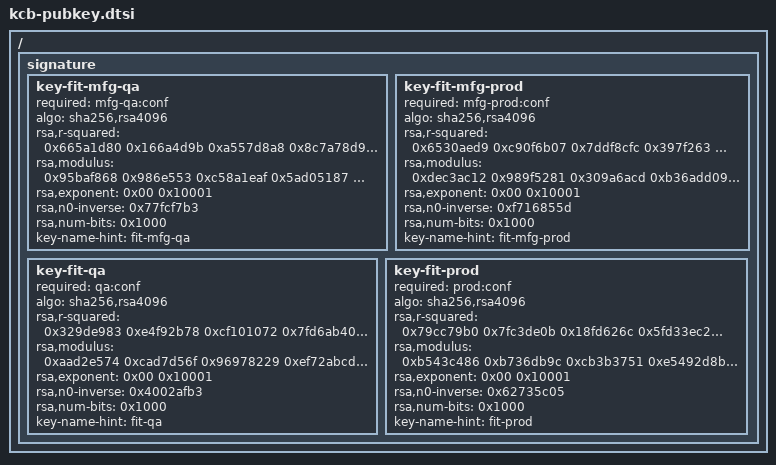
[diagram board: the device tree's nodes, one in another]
/*
 * This is a Device Tree representation of the public keys that will
 * be used for FIT image verification.
 *
 * The procedure to generate this file from production keys in AWS CloudHSM is
 * avaliable here:
 * https://github.com/ChargePoint/emb-platform/blob/master/os/buildroot/package/emb-sbsigner/README.md
 */

/ {
	signature {

		key-fit-mfg-qa {
			required = "mfg-qa:conf";
			algo = "sha256,rsa4096";
			rsa,r-squared = < 0x665a1d80 0x166a4d9b 0xa557d8a8 0x8c7a78d9 0xf4e15c7b 0x11d93e83 0x64c54e9 0x7944ce6d 0x9000c1e 0x2295f4a 0xd1a5fc97 0x77da3ca4 0x1b8357ea 0x234455da 0x6d49fc74 0xb5c791c3 0x6a1985e 0xd7bc98fe 0x99637999 0x23d22882 0xdf1b20ab 0xff6c3c1a 0x8fd6c9c0 0x9d0add75 0xc0ef7f4 0x50fc9978 0xc47e80b2 0x6f125df8 0xec1073dc 0x2f2a7b23 0xad07317b 0x1400cfc0 0x6a585a28 0x58035780 0xa6b94682 0x820d5604 0xa53b9264 0xca8510c2 0xe2faae05 0xe184be7d 0xabcadbfc 0x46a3d077 0x3e004b39 0x4a07fcae 0x2660e2df 0x7a564f5b 0xd662b66 0x24f41f32 0xe8a6f6ba 0xe0b936cc 0x3c117b2e 0x5bb8b08b 0xbe9539f 0xf0b96eed 0x78cf169c 0x366a11bb 0x7a88ccee 0xa0d228f0 0xa6286849 0xae9a5153 0xed4c8f47 0x65d77a7d 0xf5faf94f 0x6355354f 0xbc6f77ae 0x71292cf 0xeada07a4 0x3f66607f 0xf7903a5e 0xdbd3837d 0x27178acb 0xa314230c 0x648adc27 0x171ced02 0xe3ffe486 0x7680e5fa 0x5f1511e7 0xc39d7470 0x4a8c0c61 0x90b3ad1f 0x6a96369b 0xf6d0c01a 0x34ad94e5 0x8c3051bd 0xc1ac5da6 0x318d077a 0x41f7cdbb 0x6f7f253d 0x4dad6e19 0x1519bc15 0xc6d3a77f 0x11921fbf 0x3f651807 0xe66b9d78 0xec6acb9c 0xcce77610 0xc942a9e7 0xfe8b93c2 0x5f5dee2c 0x10aaddc8 0xbf092e31 0x4ace182f 0x5bd5b84 0x7e3dd261 0x1323e825 0x6c4ae565 0x42d04632 0x787533b 0xde8bde8d 0xbb8170a1 0x7d350d0b 0x1bdedb5c 0xa7bf46c4 0x362c3ac1 0x4815d47f 0x5c8d2e98 0xe0408e65 0x32ad9b76 0x66ce398e 0xffe2d7ac 0xa14f52d0 0xb356d627 0x363041f8 0xa34d1052 0x7e8841ad 0x3e4e854e 0xde868242 0x19837be6 >;
			rsa,modulus = < 0x95baf868 0x986e553 0xc58a1eaf 0x5ad05187 0x7ce40511 0x86014554 0xb3c815d9 0x901bd41e 0x43239485 0x18defb91 0xd405c901 0x937d3d73 0x4b5d996e 0x49013fc8 0x520905b 0x4907d265 0x74e9965e 0xa2f64a33 0x5e23236e 0xa621313d 0x32318fe1 0x2b8642b 0xec9756b7 0x1768c628 0xcb2e6487 0xb4c4f324 0x4c3b3e87 0x6fc41ca8 0x5b96bf1d 0x52787842 0xb1a60463 0x57fab426 0x548b10df 0x708c9e34 0x7a86e6eb 0x8346990d 0x5a221779 0x8c36c9b5 0xd485b546 0xcbac1bd4 0x68e064c1 0xf93f17cf 0xeb964a31 0x2fa5f456 0x497ccddc 0x99c38950 0xb209ac0e 0xd881d00b 0xfd7b074f 0x40500044 0x25fb6454 0xdef0664e 0x6004b7c6 0xfe23c787 0x6018945e 0x42ca113f 0x1d92036c 0xa0869953 0x6ed8e283 0xd9fe6b4a 0x9474b3fb 0xa3487675 0xee8cbb9f 0x77d65730 0x31c7ab0b 0x9c8635bb 0x1c6a4768 0x533cf705 0xd94d1691 0x18b6ac7e 0xbe3ce926 0x38fb4fa5 0x5a768315 0x118627ba 0x398c150a 0x1f08e67f 0x12fe838b 0xe1f0319f 0xf67ca964 0x1da8f6e5 0x4af92c55 0x8b1b479 0x5b8c942f 0xb7ee292 0x5781db32 0xa836320a 0xfd6374ad 0x2d4cb2d7 0xaafaf79a 0x5994ed63 0xdec3a71e 0x733b630c 0xf2f8826c 0x6cab20a1 0x9b09b897 0xc0703c9e 0x510bbe87 0xc1a5be9e 0x3fe6b7a 0x26d2068e 0x3fa08838 0xfa927363 0x5ee35f18 0x1c86c851 0x8976d97a 0xef71def4 0xa5d2d66b 0xb6a63d0c 0xb632811a 0xe6fc1176 0xf1a12d01 0xc3577fb 0x100e6c3e 0x734535a0 0x4e883689 0xc6362ad0 0x72e5fb9b 0x15941d88 0x49cf0a0d 0xc1c5c987 0x600df83 0x827905ba 0xdf28dab4 0x4576ffd3 0x12212c14 0xb9d31561 0x9654d0fe 0x43777085 >;
			rsa,exponent = < 0x00 0x10001 >;
			rsa,n0-inverse = < 0x77fcf7b3 >;
			rsa,num-bits = < 0x1000 >;
			key-name-hint = "fit-mfg-qa";
		};

		key-fit-mfg-prod {
			required = "mfg-prod:conf";
			algo = "sha256,rsa4096";
			rsa,r-squared = < 0x6530aed9 0xc90f6b07 0x7ddf8cfc 0x397f263 0x447e964f 0x468cea87 0x38af5adc 0xf4a42d1f 0x59ecaecf 0xd216f09 0x818d93e 0xb25de89 0xe0ef48ce 0xe1ab2158 0xbd1cae78 0xec078ef8 0x1c44b711 0xa61aae4a 0x18458872 0x879389bb 0xa29663d0 0x58661d9c 0x401fbf5e 0xe2b112a8 0xf26953e7 0xf081550d 0xf03f828e 0x460cc5b2 0xe991d252 0x4e60ca01 0xe0c2f80d 0x8c521f46 0x44655ccb 0xb51f60ec 0x62750c93 0xfb07dd4a 0x817e97f6 0xd6853c02 0xb2169907 0x354f9 0xbc2ba728 0x6983cbfe 0xb3e90779 0x8d121e9c 0xe84bb6f9 0x77c1e260 0x3d374193 0x41948878 0xb6da228b 0x94dc9473 0x10d7fba0 0xe90d214a 0x241862d1 0x1b3dd3ff 0xb026b871 0xfa5a4d23 0x879b2a11 0xa967ca89 0x690c68dc 0x1d0b27d9 0x7dd14669 0x4f2be452 0x42a78469 0x396b3dd1 0x7bea96 0x72c8e6b7 0x7f81c043 0x81c20251 0xfbf4cb2b 0x598a22c4 0x69aa6c32 0x44903b07 0xf2fc2b65 0x1e8d30b1 0x7530cad8 0x3791fc53 0x519f8f4c 0x5e668b56 0xc84a138d 0x5282b97a 0x3786e085 0xab014f5e 0xd55dce3c 0x643e7777 0x874a6dfb 0x6da806af 0xbc05f913 0xc4142be4 0x6fb4231d 0x65bf036b 0x38d49fd3 0xf378d8c7 0xcf81e3b4 0xc1abf106 0x962822e0 0x8b5ad19c 0x7d976a11 0x26e16da9 0x23d531d6 0x6ba3a07d 0x862ee83d 0x18bfc294 0x808aebb3 0x74c178b4 0x4e9124bb 0x7c2f21cc 0x9c39c1c7 0x14470bd 0x6fe64f00 0x85ee086d 0x4de95dcf 0x463e4eaf 0x7bc21b88 0xb0e12312 0x6a773f45 0xe6dc068b 0xb0b8cbf 0xce642af2 0x71a737d3 0x2826e57d 0xd6bd9c94 0x96aa1787 0x4432ba50 0x200ac7d3 0x2898c832 0x77e04d9d 0x31f80a71 0x26aa3f49 >;
			rsa,modulus = < 0xdec3ac12 0x989f5281 0x309a6acd 0xb36add09 0x82cf2881 0x7c807d85 0xf091a9b0 0xb5b464d 0x5328e494 0x284b67d0 0x1a620d34 0xfd6c278 0xc7bcbb0a 0xc157f7dc 0xfd741521 0x906061b0 0xb62c43d7 0x4d7fdcc 0x98acd57c 0xca05f664 0xd330aca4 0xe32b3161 0xc75e039c 0xb574df5f 0xb506eaf2 0xc721edb0 0x92276684 0xcfa73716 0xb9e73f17 0xbef008f 0xc5e1f72b 0x78623de7 0xac80d3ff 0xddf2c332 0x8ec6971 0x3bc2313 0x9d644dfe 0x8d930a0 0xbaa87cd5 0xc0d80ad9 0xf63e9ede 0xf08ca23b 0x1adac644 0x1257d918 0xfe82133 0xc3148cc2 0xa9c69531 0x2ee84904 0xa6bd2870 0x6a7bf93c 0x960dbe7c 0x56d799e6 0x1919631a 0x17b26518 0x7e568e37 0xb0ca2e9d 0x48f45a2e 0x6b22057a 0x96acf7f8 0xc2cc811b 0xcdaa0110 0x8cc8c082 0xb35696fa 0xb742a3db 0xd503ec37 0xa392e2be 0xb779d8f 0xe90ebd9d 0x324243c2 0xd63182fb 0x67dc3eb8 0xf3f083c5 0xc6dfc5fc 0x1fd3608a 0xdccab82a 0xbb3e17a 0x5b58df2e 0xa35ae29b 0x2e72caec 0xb38f5392 0x70bb59d6 0x37cea7f4 0xa37ad698 0x1154cf58 0x6ac947c4 0x888e0cf1 0x69c9456c 0xb56e39b7 0x59c927b1 0xa4b3f5e1 0x9da87d07 0x7fac7d3a 0x43b19eef 0xc3966f49 0xc85b6d24 0xe1174524 0x8db07179 0x703df686 0xa6416bd5 0x3fc1938e 0xc998168a 0x53a7704 0x687dbb13 0x48bc8a0 0x2cb4d29e 0x34cb759c 0x821a7f8 0xc2c2f87c 0xadd55119 0x9f657819 0x6e5d6c37 0x560320bf 0x82ff0b8c 0x36602ce3 0x38c8b45f 0x5bf899c0 0xa1f9e46a 0xdee7e23d 0xc5020370 0xf62644df 0xb442a8fc 0xa10d081b 0x9ab9a7b 0xe4c90dae 0x5c3aad30 0xfcce34ac 0xe41163bc 0x6738090b >;
			rsa,exponent = < 0x00 0x10001 >;
			rsa,n0-inverse = < 0xf716855d >;
			rsa,num-bits = < 0x1000 >;
			key-name-hint = "fit-mfg-prod";
		};

		key-fit-qa {
			required = "qa:conf";
			algo = "sha256,rsa4096";
			rsa,r-squared = < 0x329de983 0xe4f92b78 0xcf101072 0x7fd6ab40 0x157e59af 0xc1a78b92 0xb94cb04b 0xb9ba3528 0x357234b 0x1a10217c 0x36ac84f0 0x33a30730 0xe63306aa 0xd62369af 0x1bf3cab3 0xffbb5551 0xbd310632 0x416a2137 0x4bf5ac3b 0x6db17e21 0xd2dd36f6 0x32a1ab4e 0x418d6247 0x1dc7d282 0xcebbe3e0 0xe72be447 0xd7e26d2f 0x7ad54a8e 0x42e74184 0x87418b4a 0x46265ee 0x84c6775d 0x13caa243 0xdbc81fa7 0x96341fcb 0xcda23404 0xbea4a853 0x69e87aae 0x960ad7ba 0x8b5f5627 0xfa9a8291 0xcbd63883 0x20008885 0xa97818a3 0xf0902ed6 0xefbd7ae5 0x219efdec 0xae0bd7c0 0xded898a 0x47d266f8 0x54f19218 0xdf7283b8 0x788c3692 0x5072eaf5 0x5f206e15 0xda86467b 0xb677a840 0x8405c0db 0x2cc1eb13 0x1ee4f492 0x2ecbb70b 0x16507d4 0xea24827e 0x46a433f1 0xc7e0ab9a 0xc77e7f76 0x8e51d831 0xd071cc06 0x9afabccf 0x277ea53 0xb0a82ed 0x7fa851fc 0xdea9f0ef 0x99e13e74 0x5f2af4fe 0xd4b37208 0x9f232e6e 0x3658370d 0x6e471d1e 0x7f7597f7 0x128624bc 0xe9e24a0 0x3fa78144 0x4e391483 0x613c97b7 0x302523ec 0xa84cb413 0x60541ee0 0x653c937a 0x5f42b56b 0xcda3b31c 0x3b664ea1 0x1f6715b4 0xd822e001 0x35667953 0x657e9346 0x89579dcd 0xca58f713 0xe0bb181a 0xbd8353f4 0xd56d8419 0xb9569bbd 0x79d91125 0xec9d81a8 0x3d999139 0x49c36d76 0x449b6901 0xafbd6a90 0x1c5d1cac 0x1dcab87a 0xa9cb0f04 0xdfa6f075 0xeca4ee87 0x1ae9ae8b 0x280c5a2b 0xe7145fe 0xe0e1d51e 0x8f7170e7 0x9d67fca5 0xe70baf7f 0xaf4a491b 0x77a4985a 0xcc9bcb3f 0xb0257f57 0x72cc2ce1 0x9db4305c 0x64f375d9 0x4584b73a >;
			rsa,modulus = < 0xaad2e574 0xcad7d56f 0x96978229 0xef72abcd 0xec887fc 0xfa1c0d69 0xe77a4f31 0x7840817e 0x8cf95110 0x69515371 0x9f5a248 0x7c4c73fb 0x5126237e 0xdafc2094 0x7dc2b48f 0x52e23243 0x25b6e881 0xf90d407c 0x22527ea0 0xfa2e29d3 0x13c30f92 0xcbdaad06 0x2bba503d 0x722fc753 0xc19d4861 0x51d70d31 0xf9b84846 0x64a95380 0xe47182c3 0x9139b1c4 0xb122034c 0xff845e8b 0x3331505d 0x52920aa5 0x96027934 0x824e6e83 0x24acb1a9 0x30a4f949 0x45d7e6f3 0xdf6c9cfc 0x1e887ab0 0x94551c13 0x746a9b7f 0xd3d09152 0x4b541e2a 0x52fc49b1 0xd62f5e24 0x78d43a43 0x680c2cce 0x479cae87 0xc4b1076c 0xbbe819e7 0x45a22818 0x7b0e66d5 0x6de8bc13 0x37913057 0x1a74edd3 0x19902352 0x9248fa8a 0x54fd79ee 0xacb39222 0x4c01cedb 0xd431876c 0xb65fb864 0xedfabe45 0xb45dec1e 0xd7701daf 0xd4323b50 0xe356de58 0x2bfdc9ff 0xa0a7a334 0xa04a749 0xb56c9aac 0xdd51a20d 0x3707e33e 0xa8ca9496 0x5f501a82 0x41be062c 0x22927118 0x876d8535 0xebc136dd 0x2f90d391 0xd6b96115 0x5bc8b9ed 0x10ac0cea 0xbcbe887b 0xb0be8be6 0x316f73 0xa7f5ecc9 0x16b3b1b 0xaeba1a31 0x2f528447 0x3b80b861 0x5ae94928 0xf08cd702 0x3a7ceafa 0x34513416 0x20905701 0xd8cb03d1 0xe8c8e3b 0x71162ee2 0x7defdbaa 0x751f262 0xc21a5c82 0x71322eb7 0xf906a3bc 0xb8424bf2 0x620b84dd 0x61a77a34 0xf566795c 0x4ff1210a 0x20d5d873 0xcbdd1712 0x5d0e7965 0xe3ba0f42 0xde989b9b 0x8b9aa9d2 0xb1b3ee17 0x8139d1d 0x1edce668 0xcc68412d 0xbe5811e0 0xa0042db2 0xd796e7e8 0x744c086f 0xe994e600 0xccd5ee93 0x8ede6885 >;
			rsa,exponent = < 0x00 0x10001 >;
			rsa,n0-inverse = < 0x4002afb3 >;
			rsa,num-bits = < 0x1000 >;
			key-name-hint = "fit-qa";
		};

		key-fit-prod {
			required = "prod:conf";
			algo = "sha256,rsa4096";
			rsa,r-squared = < 0x79cc79b0 0x7fc3de0b 0x18fd626c 0x5fd33ec2 0x7b75a0ce 0xb6266b05 0xf32ae930 0xbad6ad9d 0x677ac3f 0x1e1e5f4 0x37a95b71 0xe3a3f6ed 0xa4febde5 0x335a2e66 0x4b68aaf9 0xd90f8256 0x179ff734 0x3584e5ec 0xca215caf 0xfd25c409 0x7ca3cd0e 0xa825f6f5 0x8334b93a 0xe1e00923 0x9064da6d 0x58e57c81 0x4387f6da 0x9192f62d 0x83118237 0x5eba5615 0x8c2a956d 0xca62b073 0xd9079b08 0x89cf8246 0xe2502c93 0xf1813d58 0xf549685c 0x8fcc0e03 0x3b126c74 0x8bf4ba10 0xc3bfb339 0x819ac98a 0x10b5ef0a 0xc711163e 0x43490be4 0x4d44c204 0xd985a84a 0xe9158d91 0x61a6403d 0xf58c3ecd 0xf63fee21 0x82aa4e84 0xe996d6b 0x46529cd5 0xf689a49e 0xa7f040a2 0x1b135302 0x400edc2b 0xa9dae92f 0xe9b9d029 0xcbc6054a 0xf30aa0a8 0x8d2f5d1f 0x2da109b9 0x75d5193a 0xaff123d 0xd8e62789 0xddd8b503 0x1e208753 0xf7c7fda2 0xd199aecb 0xc79824c0 0xfdd4ad6a 0x770db18d 0x1c91b23d 0xf4c2cdbc 0xd1499cc3 0x2df79e85 0x36477ed0 0xa06e94ed 0x7a67eb59 0xb3dd682c 0x41c0a11b 0xc7eafd31 0xc1df1291 0xbb74d5f4 0x762fd51b 0x520d6842 0x108856ef 0xf5c1c752 0xd9e71df0 0x8ea8c535 0x864e24ab 0xad7995f8 0xcfb085c 0x32f0b667 0xdb1b0350 0x82ea75ea 0xcca52bc5 0x39f23a9d 0xeeae4151 0xdbe33b57 0xa8a3384c 0x855c1915 0x6b22da03 0xfcd59e71 0x101ceb2d 0xc7d28e09 0xa5d9dccb 0x72706cc4 0xd157cf24 0x3ed74a81 0x3b613dcd 0xbe4297d 0x365c68a8 0xdc92686c 0xc938d410 0x9769eccf 0x36ca2fe6 0x105408f1 0x110ba3c8 0x62b05e3a 0xaacd8568 0xcb05393b 0xb7c592a8 0xe3997dcd 0x49d7adfa 0x456acf15 >;
			rsa,modulus = < 0xb543c486 0xb736db9c 0xcb3b3751 0xe5492d8b 0x8987efd9 0x5a8704cb 0xa80997dd 0x44b280e8 0x4a0cee40 0x9e46267c 0x2e4159bf 0xe22a4af3 0xdf647f0a 0x1d018c63 0x5f603a7f 0xd8eb2225 0xba9a2a64 0x3adc9a68 0x8fb9c285 0xeacc97bb 0x259238a1 0x796c926d 0xd773afd5 0xf3635a40 0x824b16ab 0x87191097 0x671539e1 0x79f1687f 0x9264ea1c 0x597a1efe 0x4b087348 0xc37a9a55 0x57492259 0x76ab2fa9 0xb8656086 0xc068bfab 0xde44c6aa 0x489e46fd 0x2fe3392b 0x461d841c 0x9e7927f9 0x5b38e1f1 0x56ae065a 0x3fc4f9f4 0xc3f0bfaf 0xf6427361 0x2ba65fe2 0x348d7ff9 0xf165ce4 0xaa9c5108 0xa3ad41e0 0xeb285853 0x4b3951c5 0x5bd54480 0x6a704bc 0xc2f174eb 0x5ee5a863 0x400fc5a4 0x455395eb 0xe69a1cf7 0xb9800f09 0x71d6b557 0x48ea8655 0xb8a6321 0x64f8450c 0x9afe28a4 0x66dd320f 0xcd2aa84 0x5ddb8c5 0x25d7c23e 0x44d56ffc 0x9c44cae5 0xe1298dc0 0x1b113b6b 0xb28f7a90 0x56f5c592 0xeaf83a12 0xcf9c67d6 0x7cde9a80 0xb44a932f 0xc1cb3757 0xc6928440 0xcf6b89d1 0x7e31e6c5 0x913cbc4c 0x3c88ab58 0x41df2aa3 0xac57274b 0xcec14d35 0x7f0018a9 0x7393ad21 0x9e9e02a6 0x4854f5b 0xef1e51b6 0x71651b7e 0x5a0708b9 0x94bca177 0x9c965d7b 0x6c57e888 0x3903f6dd 0x50cf2537 0x72c7cbed 0xbfff0163 0x9bfdf6c6 0x27fbba44 0x15c5ce63 0x6b606a24 0xcb6292ee 0x5d3344be 0xe876f528 0xb908e0ce 0xaa771354 0xd3f0da01 0x897ee487 0x7d6729fc 0xe71b24 0xf58377f7 0x9f3f3592 0xdaeda324 0x33382dda 0xc4116f12 0x94b0f34d 0xd159e04a 0x37361a9f 0xb2b98a15 0x2d025ffb 0x88b98054 0xc66cef33 >;
			rsa,exponent = < 0x00 0x10001 >;
			rsa,n0-inverse = < 0x62735c05 >;
			rsa,num-bits = < 0x1000 >;
			key-name-hint = "fit-prod";
		};
	};
};

